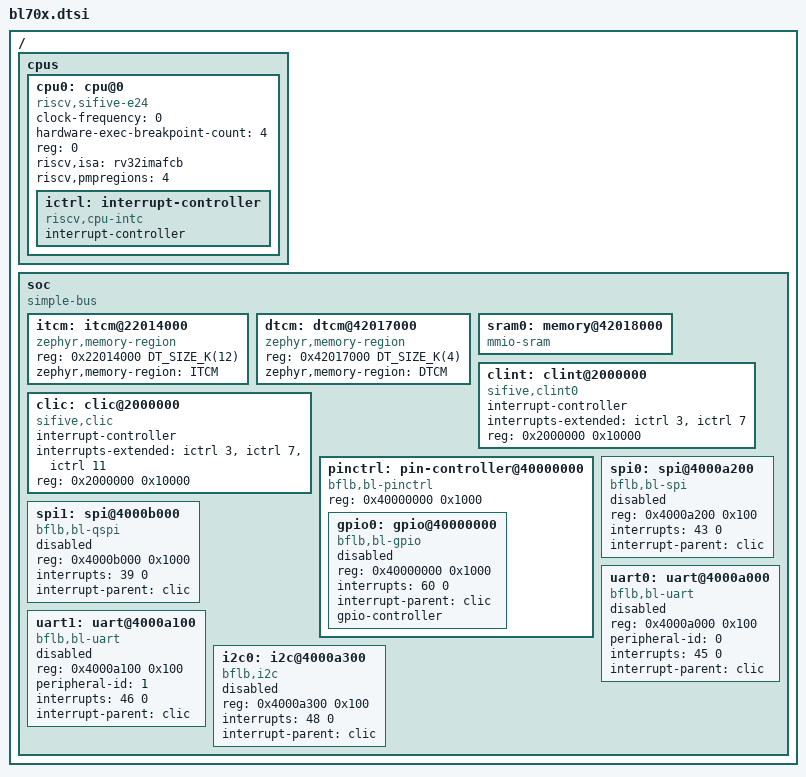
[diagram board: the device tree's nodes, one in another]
/*
 * Copyright (c) 2021, ATL Electronics
 *
 * SPDX-License-Identifier: Apache-2.0
 */

#include <mem.h>
#include <dt-bindings/pinctrl/bl70x-pinctrl.h>
#include <dt-bindings/pinctrl/bflb-common-pinctrl.h>

/ {
	#address-cells = <1>;
	#size-cells = <1>;

	cpus {
		#address-cells = <1>;
		#size-cells = <0>;

		cpu0: cpu@0 {
			clock-frequency = <0>;
			compatible = "riscv,sifive-e24", "riscv";
			device_type = "cpu";
			hardware-exec-breakpoint-count = <4>;
			reg = <0>;
			riscv,isa = "rv32imafcb";
			riscv,pmpregions = <4>;

			ictrl: interrupt-controller {
				#address-cells = <0>;
				#interrupt-cells = <1>;
				compatible = "riscv,cpu-intc";
				interrupt-controller;
			};
		};
	};

	soc {
		#address-cells = <1>;
		#size-cells = <1>;
		compatible = "simple-bus";
		ranges;

		itcm: itcm@22014000 {
			compatible = "zephyr,memory-region", "sifive,dtim0";
			reg = <0x22014000 DT_SIZE_K(12)>;
			zephyr,memory-region = "ITCM";
		};
		dtcm: dtcm@42017000 {
			compatible = "zephyr,memory-region", "sifive,dtim0";
			reg = <0x42017000 DT_SIZE_K(4)>;
			zephyr,memory-region = "DTCM";
		};

		sram0: memory@42018000 {
			compatible = "mmio-sram";
		};

		clint: clint@2000000 {
			#address-cells = <0>;
			#interrupt-cells = <1>;
			interrupt-controller;
			compatible = "sifive,clint0";
			interrupts-extended = <&ictrl 3 &ictrl 7>;
			reg = <0x2000000 0x10000>;
			reg-names = "control";
		};

		clic: clic@2000000 {
			#interrupt-cells = <2>;
			interrupt-controller;
			compatible = "sifive,clic";
			interrupts-extended = <&ictrl 3 &ictrl 7 &ictrl 11>;
			reg = <0x2000000 0x10000>;
			reg-names = "control";
/*
			sifive,numintbits = <4>;
			sifive,numints = <64>;
			sifive,numlevels = <16>;
*/
		};

		pinctrl: pin-controller@40000000 {
			compatible = "bflb,bl-pinctrl";
			reg = <0x40000000 0x1000>;
			#address-cells = <1>;
			#size-cells = <1>;
			ranges = <0x40000000 0x40000000 0x1000>;
			status = "okay";

			gpio0: gpio@40000000 {
				compatible = "bflb,bl-gpio";
				reg = <0x40000000 0x1000>;
				interrupts = <60 0>;
				interrupt-parent = <&clic>;
				gpio-controller;
				#gpio-cells = <2>;
				#bflb,pin-cells = <2>;
				status = "disabled";
			};
		};

		spi0: spi@4000a200 {
			compatible = "bflb,bl-spi";
			reg = <0x4000a200 0x100>;
			interrupts = <43 0>;
			interrupt-parent = <&clic>;
			status = "disabled";
			#address-cells = <1>;
			#size-cells = <0>;
		};

		spi1: spi@4000b000 {
			compatible = "bflb,bl-qspi";
			reg = <0x4000b000 0x1000>;
			interrupts = <39 0>;
			interrupt-parent = <&clic>;
			status = "disabled";
			#address-cells = <1>;
			#size-cells = <0>;
		};

		uart0: uart@4000a000 {
			compatible = "bflb,bl-uart";
			reg = <0x4000a000 0x100>;
			peripheral-id = <0>;
			interrupts = <45 0>;
			interrupt-parent = <&clic>;
			status = "disabled";
		};
		uart1: uart@4000a100 {
			compatible = "bflb,bl-uart";
			reg = <0x4000a100 0x100>;
			peripheral-id = <1>;
			interrupts = <46 0>;
			interrupt-parent = <&clic>;
			status = "disabled";
		};
		i2c0: i2c@4000a300 {
			compatible = "bflb,i2c";
			reg = <0x4000a300 0x100>;
			interrupts = <48 0>;
			interrupt-parent = <&clic>;
			status = "disabled";
			#address-cells = <1>;
			#size-cells = <0>;
		};
	};
};
